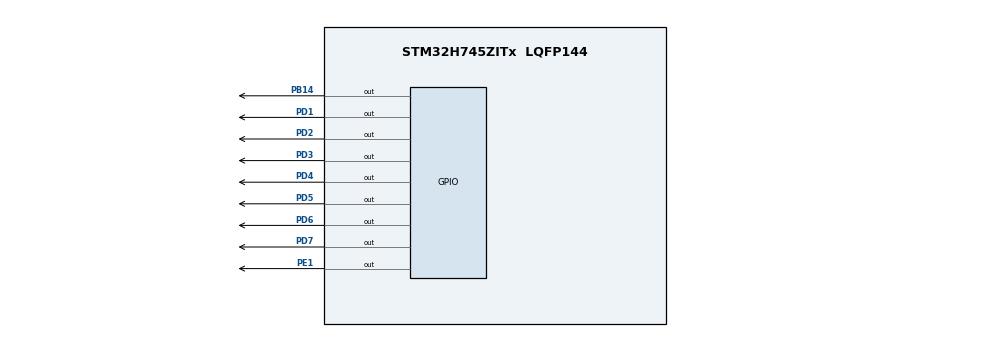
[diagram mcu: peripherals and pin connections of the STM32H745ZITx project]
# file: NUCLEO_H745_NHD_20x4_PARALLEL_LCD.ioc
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CORTEX_M7.CPU_DCache=Enabled
CORTEX_M7.CPU_ICache=Enabled
CortexM4.IPs=FATFS_M4\:I,FREERTOS_M4\:I,IWDG2\:I,RCC,WWDG2\:I,DMA,BDMA,MDMA,NVIC2\:I,USART3,ETH,DEBUG,USB_DEVICE_M4\:I,USB_HOST_M4\:I,PDM2PCM_M4\:I,PWR,RESMGR_UTILITY,SYS_M4\:I,CORTEX_M4\:I,OPENAMP_M4\:I,VREFBUF
CortexM4.Pins=PE1
CortexM7.IPs=FATFS_M7\:I,FREERTOS_M7\:I,IWDG1\:I,RCC\:I,WWDG1\:I,DMA\:I,BDMA\:I,MDMA\:I,NVIC1\:I,SYS\:I,USART3\:I,USB_OTG_FS\:I,ETH\:I,CORTEX_M7\:I,DEBUG\:I,USB_DEVICE_M7\:I,USB_HOST_M7\:I,PDM2PCM_M7\:I,PWR\:I,RESMGR_UTILITY\:I,OPENAMP_M7\:I,VREFBUF\:I,TIM1\:I
CortexM7.Pins=PB14,PD1,PD2,PD3,PD4,PD5,PD6,PD7
Mcu.Family=STM32H7
Mcu.Name=STM32H745ZITx
Mcu.Package=LQFP144
NVIC1.PriorityGroup=NVIC_PRIORITYGROUP_4
NVIC2.PriorityGroup=NVIC_PRIORITYGROUP_4
PB14.PinAttribute=CortexM7
PB14.Signal=GPIO_Output
PD1.PinAttribute=CortexM7
PD1.Signal=GPIO_Output
PD2.PinAttribute=CortexM7
PD2.Signal=GPIO_Output
PD3.PinAttribute=CortexM7
PD3.Signal=GPIO_Output
PD4.PinAttribute=CortexM7
PD4.Signal=GPIO_Output
PD5.PinAttribute=CortexM7
PD5.Signal=GPIO_Output
PD6.PinAttribute=CortexM7
PD6.Signal=GPIO_Output
PD7.PinAttribute=CortexM7
PD7.Signal=GPIO_Output
PE1.PinAttribute=CortexM4
PE1.Signal=GPIO_Output
PH0-OSC_IN\ (PH0).Mode=HSE-External-Oscillator
PH0-OSC_IN\ (PH0).PinAttribute=CortexM7
PH0-OSC_IN\ (PH0).Signal=RCC_OSC_IN
PH1-OSC_OUT\ (PH1).Mode=HSE-External-Oscillator
PH1-OSC_OUT\ (PH1).PinAttribute=CortexM7
PH1-OSC_OUT\ (PH1).Signal=RCC_OSC_OUT
ProjectManager.HeapSize=M4-0x200,M7-0x200
ProjectManager.StackSize=M4-0x400,M7-0x400
ProjectManager.TargetToolchain=STM32CubeIDE
RCC.ADCFreq_Value=50390625
RCC.APB1Freq_Value=100000000
RCC.APB2Freq_Value=100000000
RCC.APB3Freq_Value=100000000
RCC.APB4Freq_Value=100000000
RCC.CortexFreq_Value=400000000
RCC.D1PPRE=RCC_APB3_DIV2
RCC.D2PPRE1=RCC_APB1_DIV2
RCC.D2PPRE2=RCC_APB2_DIV2
RCC.D3PPRE=RCC_APB4_DIV2
RCC.DIVM1=5
RCC.DIVM3=1
RCC.DIVN1=160
RCC.DIVN3=24
RCC.DIVQ3=4
RCC.HCLKFreq_Value=200000000
RCC.HPRE=RCC_HCLK_DIV2
RCC.HSE_VALUE=25000000
RCC.PLL2FRACN=0
RCC.PLL3FRACN=0
RCC.PLLFRACN=0
RCC.PLLSourceVirtual=RCC_PLLSOURCE_HSE
RCC.SYSCLKFreq_VALUE=400000000
RCC.SYSCLKSource=RCC_SYSCLKSOURCE_PLLCLK
RCC.SupplySource=PWR_DIRECT_SMPS_SUPPLY
RCC.USBCLockSelection=RCC_USBCLKSOURCE_PLL3
RCC.USBFreq_Value=150000000
TIM1.Prescaler=1-1
VP_SYS_M4_VS_Systick.Mode=SysTick
VP_TIM1_VS_ClockSourceINT.Mode=Internal
board=NUCLEO-H745ZI-Q

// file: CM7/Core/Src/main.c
/* USER CODE BEGIN Header */
/**
  ******************************************************************************
  * @file           : main.c
  * @brief          : Main program body
  ******************************************************************************
  * @attention
  *
  * <h2><center>&copy; Copyright (c) 2021 STMicroelectronics.
  * All rights reserved.</center></h2>
  *
  * This software component is licensed by ST under BSD 3-Clause license,
  * the "License"; You may not use this file except in compliance with the
  * License. You may obtain a copy of the License at:
  *                        opensource.org/licenses/BSD-3-Clause
  *
  ******************************************************************************
  */
/* USER CODE END Header */
#include "main.h"
#include "nhd_20x4_LCD.h"

/* USER CODE BEGIN PD */

#ifndef HSEM_ID_0
#define HSEM_ID_0 (0U) /* HW semaphore 0*/
#endif
/* USER CODE END PD */

TIM_HandleTypeDef htim1;

void SystemClock_Config(void);
static void MX_GPIO_Init(void);
static void MX_TIM1_Init(void);

int main(void)
{
/* USER CODE BEGIN Boot_Mode_Sequence_0 */
  int32_t timeout;
/* USER CODE END Boot_Mode_Sequence_0 */

  /* Enable I-Cache---------------------------------------------------------*/
  SCB_EnableICache();

  /* Enable D-Cache---------------------------------------------------------*/
  SCB_EnableDCache();

/* USER CODE BEGIN Boot_Mode_Sequence_1 */
  /* Wait until CPU2 boots and enters in stop mode or timeout*/
  timeout = 0xFFFF;
  while((__HAL_RCC_GET_FLAG(RCC_FLAG_D2CKRDY) != RESET) && (timeout-- > 0));
  if ( timeout < 0 )
  {
  Error_Handler();
  }
/* USER CODE END Boot_Mode_Sequence_1 */
  /* MCU Configuration--------------------------------------------------------*/

  /* Reset of all peripherals, Initializes the Flash interface and the Systick. */
  HAL_Init();

  /* Configure the system clock */
  SystemClock_Config();
/* USER CODE BEGIN Boot_Mode_Sequence_2 */
/* When system initialization is finished, Cortex-M7 will release Cortex-M4 by means of
HSEM notification */
/*HW semaphore Clock enable*/
__HAL_RCC_HSEM_CLK_ENABLE();
/*Take HSEM */
HAL_HSEM_FastTake(HSEM_ID_0);
/*Release HSEM in order to notify the CPU2(CM4)*/
HAL_HSEM_Release(HSEM_ID_0,0);
/* wait until CPU2 wakes up from stop mode */
timeout = 0xFFFF;
while((__HAL_RCC_GET_FLAG(RCC_FLAG_D2CKRDY) == RESET) && (timeout-- > 0));
if ( timeout < 0 )
{
Error_Handler();
}
/* USER CODE END Boot_Mode_Sequence_2 */

  /* Initialize all configured peripherals */
  MX_GPIO_Init();
  MX_TIM1_Init();
  nhd_LCD_Init();
  /* USER CODE BEGIN 2 */

  lcd_send_string("HELLO ");
  HAL_Delay(100);
  lcd_send_string("WORLD ");
  HAL_Delay(100);
  lcd_send_string("FROM");
  HAL_Delay(100);
  lcd_put_cur(1, 0);
  lcd_send_string("KRISSSTIANN!!!!!!!");

  /* USER CODE END 2 */

  /* Infinite loop */
  while (1)
  {

  }
}

void SystemClock_Config(void)
{
  RCC_OscInitTypeDef RCC_OscInitStruct = {0};
  RCC_ClkInitTypeDef RCC_ClkInitStruct = {0};

  /** Supply configuration update enable
  */
  HAL_PWREx_ConfigSupply(PWR_DIRECT_SMPS_SUPPLY);
  /** Configure the main internal regulator output voltage
  */
  __HAL_PWR_VOLTAGESCALING_CONFIG(PWR_REGULATOR_VOLTAGE_SCALE1);

  while(!__HAL_PWR_GET_FLAG(PWR_FLAG_VOSRDY)) {}
  /** Initializes the RCC Oscillators according to the specified parameters
  * in the RCC_OscInitTypeDef structure.
  */
  RCC_OscInitStruct.OscillatorType = RCC_OSCILLATORTYPE_HSE;
  RCC_OscInitStruct.HSEState = RCC_HSE_ON;
  RCC_OscInitStruct.PLL.PLLState = RCC_PLL_ON;
  RCC_OscInitStruct.PLL.PLLSource = RCC_PLLSOURCE_HSE;
  RCC_OscInitStruct.PLL.PLLM = 5;
  RCC_OscInitStruct.PLL.PLLN = 160;
  RCC_OscInitStruct.PLL.PLLP = 2;
  RCC_OscInitStruct.PLL.PLLQ = 2;
  RCC_OscInitStruct.PLL.PLLR = 2;
  RCC_OscInitStruct.PLL.PLLRGE = RCC_PLL1VCIRANGE_2;
  RCC_OscInitStruct.PLL.PLLVCOSEL = RCC_PLL1VCOWIDE;
  RCC_OscInitStruct.PLL.PLLFRACN = 0;
  if (HAL_RCC_OscConfig(&RCC_OscInitStruct) != HAL_OK)
  {
    Error_Handler();
  }
  /** Initializes the CPU, AHB and APB buses clocks
  */
  RCC_ClkInitStruct.ClockType = RCC_CLOCKTYPE_HCLK|RCC_CLOCKTYPE_SYSCLK
                              |RCC_CLOCKTYPE_PCLK1|RCC_CLOCKTYPE_PCLK2
                              |RCC_CLOCKTYPE_D3PCLK1|RCC_CLOCKTYPE_D1PCLK1;
  RCC_ClkInitStruct.SYSCLKSource = RCC_SYSCLKSOURCE_PLLCLK;
  RCC_ClkInitStruct.SYSCLKDivider = RCC_SYSCLK_DIV1;
  RCC_ClkInitStruct.AHBCLKDivider = RCC_HCLK_DIV2;
  RCC_ClkInitStruct.APB3CLKDivider = RCC_APB3_DIV2;
  RCC_ClkInitStruct.APB1CLKDivider = RCC_APB1_DIV2;
  RCC_ClkInitStruct.APB2CLKDivider = RCC_APB2_DIV2;
  RCC_ClkInitStruct.APB4CLKDivider = RCC_APB4_DIV2;

  if (HAL_RCC_ClockConfig(&RCC_ClkInitStruct, FLASH_LATENCY_2) != HAL_OK)
  {
    Error_Handler();
  }
}

static void MX_TIM1_Init(void)
{

  TIM_ClockConfigTypeDef sClockSourceConfig = {0};
  TIM_MasterConfigTypeDef sMasterConfig = {0};

  htim1.Instance = TIM1;
  htim1.Init.Prescaler = 1-1;
  htim1.Init.CounterMode = TIM_COUNTERMODE_UP;
  htim1.Init.Period = 65535;
  htim1.Init.ClockDivision = TIM_CLOCKDIVISION_DIV1;
  htim1.Init.RepetitionCounter = 0;
  htim1.Init.AutoReloadPreload = TIM_AUTORELOAD_PRELOAD_DISABLE;
  if (HAL_TIM_Base_Init(&htim1) != HAL_OK)
  {
    Error_Handler();
  }
  sClockSourceConfig.ClockSource = TIM_CLOCKSOURCE_INTERNAL;
  if (HAL_TIM_ConfigClockSource(&htim1, &sClockSourceConfig) != HAL_OK)
  {
    Error_Handler();
  }
  sMasterConfig.MasterOutputTrigger = TIM_TRGO_RESET;
  sMasterConfig.MasterOutputTrigger2 = TIM_TRGO2_RESET;
  sMasterConfig.MasterSlaveMode = TIM_MASTERSLAVEMODE_DISABLE;
  if (HAL_TIMEx_MasterConfigSynchronization(&htim1, &sMasterConfig) != HAL_OK)
  {
    Error_Handler();
  }

}

static void MX_GPIO_Init(void)
{
  GPIO_InitTypeDef GPIO_InitStruct = {0};

  /* GPIO Ports Clock Enable */
  __HAL_RCC_GPIOH_CLK_ENABLE();
  __HAL_RCC_GPIOB_CLK_ENABLE();
  __HAL_RCC_GPIOD_CLK_ENABLE();

  /*Configure GPIO pin Output Level */
  HAL_GPIO_WritePin(GPIOB, GPIO_PIN_14, GPIO_PIN_RESET);

  /*Configure GPIO pin Output Level */
  HAL_GPIO_WritePin(GPIOD, GPIO_PIN_1|GPIO_PIN_2|GPIO_PIN_3|GPIO_PIN_4
                          |GPIO_PIN_5|GPIO_PIN_6|GPIO_PIN_7, GPIO_PIN_RESET);

  /*Configure GPIO pin : PB14 */
  GPIO_InitStruct.Pin = GPIO_PIN_14;
  GPIO_InitStruct.Mode = GPIO_MODE_OUTPUT_PP;
  GPIO_InitStruct.Pull = GPIO_NOPULL;
  GPIO_InitStruct.Speed = GPIO_SPEED_FREQ_LOW;
  HAL_GPIO_Init(GPIOB, &GPIO_InitStruct);

  /*Configure GPIO pins : PD1 PD2 PD3 PD4
                           PD5 PD6 PD7 */
  GPIO_InitStruct.Pin = GPIO_PIN_1|GPIO_PIN_2|GPIO_PIN_3|GPIO_PIN_4
                          |GPIO_PIN_5|GPIO_PIN_6|GPIO_PIN_7;
  GPIO_InitStruct.Mode = GPIO_MODE_OUTPUT_PP;
  GPIO_InitStruct.Pull = GPIO_NOPULL;
  GPIO_InitStruct.Speed = GPIO_SPEED_FREQ_LOW;
  HAL_GPIO_Init(GPIOD, &GPIO_InitStruct);

}

void Error_Handler(void)
{
  __disable_irq();
  while (1)
  {
  }
}

/************************ (C) COPYRIGHT STMicroelectronics *****END OF FILE****/
